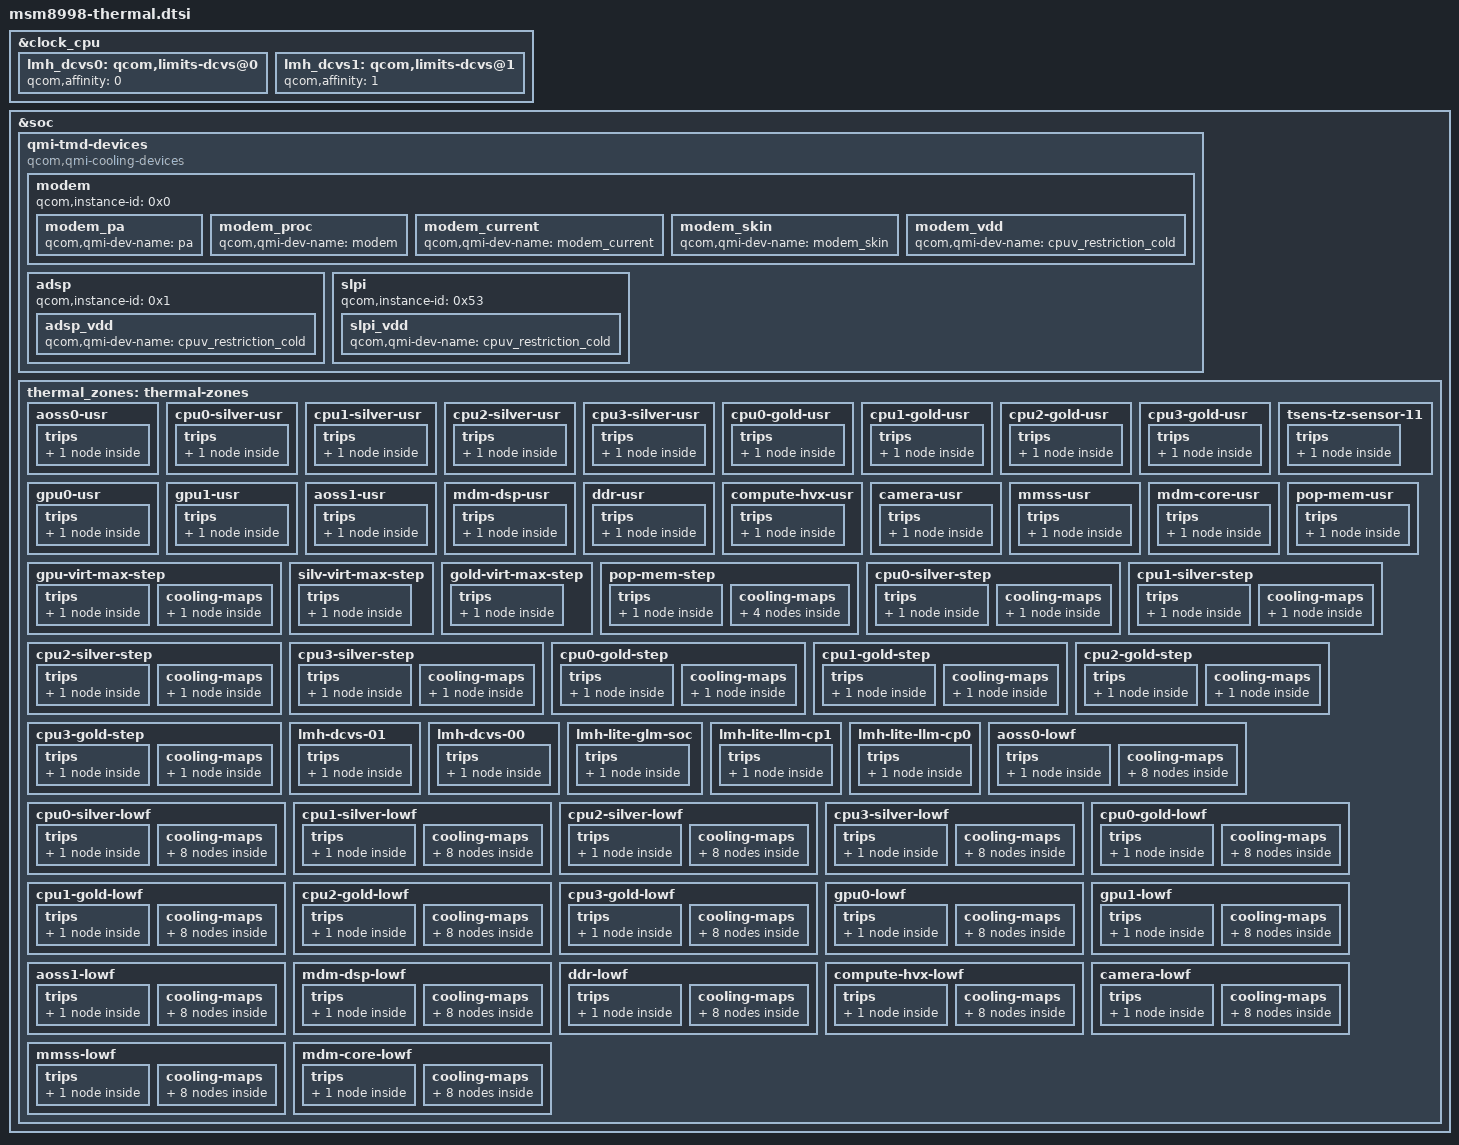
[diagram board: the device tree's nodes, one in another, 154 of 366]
/* Copyright (c) 2017-2018, The Linux Foundation. All rights reserved.
 * Copyright (C) 2018, AngeloGioacchino Del Regno <kholk11@gmail.com>
 *
 * This program is free software; you can redistribute it and/or modify
 * it under the terms of the GNU General Public License version 2 and
 * only version 2 as published by the Free Software Foundation.
 *
 * This program is distributed in the hope that it will be useful,
 * but WITHOUT ANY WARRANTY; without even the implied warranty of
 * MERCHANTABILITY or FITNESS FOR A PARTICULAR PURPOSE.  See the
 * GNU General Public License for more details.
 */

#include <dt-bindings/thermal/thermal.h>

&clock_cpu {
	lmh_dcvs0: qcom,limits-dcvs@0 {
		qcom,affinity = <0>;
		#thermal-sensor-cells = <0>;
	};

	lmh_dcvs1: qcom,limits-dcvs@1 {
		qcom,affinity = <1>;
		#thermal-sensor-cells = <0>;
	};
};

&soc {
	qmi-tmd-devices {
		compatible = "qcom,qmi-cooling-devices";

		modem {
			qcom,instance-id = <0x0>;

			modem_pa: modem_pa {
				qcom,qmi-dev-name = "pa";
				#cooling-cells = <2>;
			};

			modem_proc: modem_proc {
				qcom,qmi-dev-name = "modem";
				#cooling-cells = <2>;
			};

			modem_current: modem_current {
				qcom,qmi-dev-name = "modem_current";
				#cooling-cells = <2>;
			};

			modem_skin: modem_skin {
				qcom,qmi-dev-name = "modem_skin";
				#cooling-cells = <2>;
			};

			modem_vdd: modem_vdd {
				qcom,qmi-dev-name = "cpuv_restriction_cold";
				#cooling-cells = <2>;
			};
		};

		adsp {
			qcom,instance-id = <0x1>;

			adsp_vdd: adsp_vdd {
				qcom,qmi-dev-name = "cpuv_restriction_cold";
				#cooling-cells = <2>;
			};
		};

		slpi {
			qcom,instance-id = <0x53>;

			slpi_vdd: slpi_vdd {
				qcom,qmi-dev-name = "cpuv_restriction_cold";
				#cooling-cells = <2>;
			};
		};
	};

	thermal_zones: thermal-zones {
		aoss0-usr {
			polling-delay-passive = <0>;
			polling-delay = <0>;
			thermal-governor = "user_space";
			thermal-sensors = <&tsens0 0>;
			trips {
				active-config0 {
					temperature = <125000>;
					hysteresis = <1000>;
					type = "passive";
				};
			};
		};

		cpu0-silver-usr {
			polling-delay-passive = <0>;
			polling-delay = <0>;
			thermal-governor = "user_space";
			thermal-sensors = <&tsens0 1>;
			trips {
				active-config0 {
					temperature = <125000>;
					hysteresis = <1000>;
					type = "passive";
				};
			};
		};

		cpu1-silver-usr {
			polling-delay-passive = <0>;
			polling-delay = <0>;
			thermal-governor = "user_space";
			thermal-sensors = <&tsens0 2>;
			trips {
				active-config0 {
					temperature = <125000>;
					hysteresis = <1000>;
					type = "passive";
				};
			};
		};

		cpu2-silver-usr {
			polling-delay-passive = <0>;
			polling-delay = <0>;
			thermal-governor = "user_space";
			thermal-sensors = <&tsens0 3>;
			trips {
				active-config0 {
					temperature = <125000>;
					hysteresis = <1000>;
					type = "passive";
				};
			};
		};

		cpu3-silver-usr {
			polling-delay-passive = <0>;
			polling-delay = <0>;
			thermal-sensors = <&tsens0 4>;
			thermal-governor = "user_space";
			trips {
				active-config0 {
					temperature = <125000>;
					hysteresis = <1000>;
					type = "passive";
				};
			};
		};

		cpu0-gold-usr {
			polling-delay-passive = <0>;
			polling-delay = <0>;
			thermal-sensors = <&tsens0 7>;
			thermal-governor = "user_space";
			trips {
				active-config0 {
					temperature = <125000>;
					hysteresis = <1000>;
					type = "passive";
				};
			};
		};

		cpu1-gold-usr {
			polling-delay-passive = <0>;
			polling-delay = <0>;
			thermal-sensors = <&tsens0 8>;
			thermal-governor = "user_space";
			trips {
				active-config0 {
					temperature = <125000>;
					hysteresis = <1000>;
					type = "passive";
				};
			};
		};

		cpu2-gold-usr {
			polling-delay-passive = <0>;
			polling-delay = <0>;
			thermal-sensors = <&tsens0 9>;
			thermal-governor = "user_space";
			trips {
				active-config0 {
					temperature = <125000>;
					hysteresis = <1000>;
					type = "passive";
				};
			};
		};

		cpu3-gold-usr {
			polling-delay-passive = <0>;
			polling-delay = <0>;
			thermal-sensors = <&tsens0 10>;
			thermal-governor = "user_space";
			trips {
				active-config0 {
					temperature = <125000>;
					hysteresis = <1000>;
					type = "passive";
				};
			};
		};

		tsens-tz-sensor-11 {
			polling-delay-passive = <0>;
			polling-delay = <0>;
			thermal-sensors = <&tsens0 11>;
			thermal-governor = "user_space";
			trips {
				active-config0 {
					temperature = <125000>;
					hysteresis = <1000>;
					type = "passive";
				};
			};
		};

		gpu0-usr {
			polling-delay-passive = <0>;
			polling-delay = <0>;
			thermal-sensors = <&tsens0 12>;
			thermal-governor = "user_space";
			trips {
				active-config0 {
					temperature = <125000>;
					hysteresis = <1000>;
					type = "passive";
				};
			};
		};

		gpu1-usr {
			polling-delay-passive = <0>;
			polling-delay = <0>;
			thermal-governor = "user_space";
			thermal-sensors = <&tsens0 13>;
			trips {
				active-config0 {
					temperature = <125000>;
					hysteresis = <1000>;
					type = "passive";
				};
			};
		};

		aoss1-usr {
			polling-delay-passive = <0>;
			polling-delay = <0>;
			thermal-sensors = <&tsens1 0>;
			thermal-governor = "user_space";
			trips {
				active-config0 {
					temperature = <125000>;
					hysteresis = <1000>;
					type = "passive";
				};
			};
		};

		mdm-dsp-usr {
			polling-delay-passive = <0>;
			polling-delay = <0>;
			thermal-sensors = <&tsens1 1>;
			thermal-governor = "user_space";
			trips {
				active-config0 {
					temperature = <125000>;
					hysteresis = <1000>;
					type = "passive";
				};
			};
		};

		ddr-usr {
			polling-delay-passive = <0>;
			polling-delay = <0>;
			thermal-sensors = <&tsens1 2>;
			thermal-governor = "user_space";
			trips {
				active-config0 {
					temperature = <125000>;
					hysteresis = <1000>;
					type = "passive";
				};
			};
		};

		compute-hvx-usr {
			polling-delay-passive = <0>;
			polling-delay = <0>;
			thermal-sensors = <&tsens1 3>;
			thermal-governor = "user_space";
			trips {
				active-config0 {
					temperature = <125000>;
					hysteresis = <1000>;
					type = "passive";
				};
			};
		};

		camera-usr {
			polling-delay-passive = <0>;
			polling-delay = <0>;
			thermal-sensors = <&tsens1 4>;
			thermal-governor = "user_space";
			trips {
				active-config0 {
					temperature = <125000>;
					hysteresis = <1000>;
					type = "passive";
				};
			};
		};

		mmss-usr {
			polling-delay-passive = <0>;
			polling-delay = <0>;
			thermal-sensors = <&tsens1 5>;
			thermal-governor = "user_space";
			trips {
				active-config0 {
					temperature = <125000>;
					hysteresis = <1000>;
					type = "passive";
				};
			};
		};

		mdm-core-usr {
			polling-delay-passive = <0>;
			polling-delay = <0>;
			thermal-sensors = <&tsens1 6>;
			thermal-governor = "user_space";
			trips {
				active-config0 {
					temperature = <125000>;
					hysteresis = <1000>;
					type = "passive";
				};
			};
		};

		pop-mem-usr {
			polling-delay-passive = <0>;
			polling-delay = <0>;
			thermal-sensors = <&tsens1 7>;
			thermal-governor = "user_space";
			trips {
				active-config0 {
					temperature = <125000>;
					hysteresis = <1000>;
					type = "passive";
				};
			};
		};

		gpu-virt-max-step {
			polling-delay-passive = <10>;
			polling-delay = <100>;
			thermal-governor = "step_wise";
			trips {
				gpu_trip0: gpu-trip0 {
					temperature = <95000>;
					hysteresis = <0>;
					type = "passive";
				};
			};
			cooling-maps {
				gpu_cdev0 {
					trip = <&gpu_trip0>;
					cooling-device =
						<&msm_gpu 0 THERMAL_NO_LIMIT>;
				};
			};
		};

		silv-virt-max-step {
			polling-delay-passive = <0>;
			polling-delay = <0>;
			thermal-governor = "step_wise";
			trips {
				silver-trip {
					temperature = <120000>;
					hysteresis = <0>;
					type = "passive";
				};
			};
		};

		gold-virt-max-step {
			polling-delay-passive = <0>;
			polling-delay = <0>;
			thermal-governor = "step_wise";
			trips {
				gold-trip {
					temperature = <120000>;
					hysteresis = <0>;
					type = "passive";
				};
			};
		};

		pop-mem-step {
			polling-delay-passive = <10>;
			polling-delay = <0>;
			thermal-sensors = <&tsens1 7>;
			thermal-governor = "step_wise";
			trips {
				pop_trip: pop-trip {
					temperature = <95000>;
					hysteresis = <0>;
					type = "passive";
				};
			};
			cooling-maps {
				pop_cdev4 {
					trip = <&pop_trip>;
					cooling-device =
						<&CPU4 THERMAL_NO_LIMIT
							(THERMAL_MAX_LIMIT-1)>;
				};
				pop_cdev5 {
					trip = <&pop_trip>;
					cooling-device =
						<&CPU5 THERMAL_NO_LIMIT
							(THERMAL_MAX_LIMIT-1)>;
				};
				pop_cdev6 {
					trip = <&pop_trip>;
					cooling-device =
						<&CPU6 THERMAL_NO_LIMIT
							(THERMAL_MAX_LIMIT-1)>;
				};
				pop_cdev7 {
					trip = <&pop_trip>;
					cooling-device =
						<&CPU7 THERMAL_NO_LIMIT
							(THERMAL_MAX_LIMIT-1)>;
				};
			};
		};

		cpu0-silver-step {
			polling-delay-passive = <100>;
			polling-delay = <0>;
			thermal-sensors = <&tsens0 1>;
			thermal-governor = "step_wise";
			trips {
				emerg_config0: emerg-config0 {
					temperature = <110000>;
					hysteresis = <10000>;
					type = "passive";
				};
			};
			cooling-maps {
				emerg_cdev0 {
					trip = <&emerg_config0>;
					cooling-device =
						<&CPU0 THERMAL_MAX_LIMIT
							THERMAL_MAX_LIMIT>;
				};
			};
		};

		cpu1-silver-step {
			polling-delay-passive = <100>;
			polling-delay = <0>;
			thermal-sensors = <&tsens0 2>;
			thermal-governor = "step_wise";
			trips {
				emerg_config1: emerg-config1 {
					temperature = <110000>;
					hysteresis = <10000>;
					type = "passive";
				};
			};
			cooling-maps {
				emerg_cdev1 {
					trip = <&emerg_config1>;
					cooling-device =
						<&CPU1 THERMAL_MAX_LIMIT
							THERMAL_MAX_LIMIT>;
				};
			};
		};

		cpu2-silver-step {
			polling-delay-passive = <100>;
			polling-delay = <0>;
			thermal-sensors = <&tsens0 3>;
			thermal-governor = "step_wise";
			trips {
				emerg_config2: emerg-config2 {
					temperature = <110000>;
					hysteresis = <10000>;
					type = "passive";
				};
			};
			cooling-maps {
				emerg_cdev2 {
					trip = <&emerg_config2>;
					cooling-device =
						<&CPU2 THERMAL_MAX_LIMIT
							THERMAL_MAX_LIMIT>;
				};
			};
		};

		cpu3-silver-step {
			polling-delay-passive = <100>;
			polling-delay = <0>;
			thermal-sensors = <&tsens0 4>;
			thermal-governor = "step_wise";
			trips {
				emerg_config3: emerg-config3 {
					temperature = <110000>;
					hysteresis = <10000>;
					type = "passive";
				};
			};
			cooling-maps {
				emerg_cdev3 {
					trip = <&emerg_config3>;
					cooling-device =
						<&CPU3 THERMAL_MAX_LIMIT
							THERMAL_MAX_LIMIT>;
				};
			};
		};

		cpu0-gold-step {
			polling-delay-passive = <100>;
			polling-delay = <0>;
			thermal-sensors = <&tsens0 7>;
			thermal-governor = "step_wise";
			trips {
				emerg_config4: emerg-config4 {
					temperature = <110000>;
					hysteresis = <10000>;
					type = "passive";
				};
			};
			cooling-maps {
				emerg_cdev4 {
					trip = <&emerg_config4>;
					cooling-device =
						<&CPU4 THERMAL_MAX_LIMIT
							THERMAL_MAX_LIMIT>;
				};
			};
		};

		cpu1-gold-step {
			polling-delay-passive = <100>;
			polling-delay = <0>;
			thermal-sensors = <&tsens0 8>;
			thermal-governor = "step_wise";
			trips {
				emerg_config5: emerg-config5 {
					temperature = <110000>;
					hysteresis = <10000>;
					type = "passive";
				};
			};
			cooling-maps {
				emerg_cdev5 {
					trip = <&emerg_config5>;
					cooling-device =
						<&CPU5 THERMAL_MAX_LIMIT
							THERMAL_MAX_LIMIT>;
				};
			};
		};

		cpu2-gold-step {
			polling-delay-passive = <100>;
			polling-delay = <0>;
			thermal-sensors = <&tsens0 9>;
			thermal-governor = "step_wise";
			trips {
				emerg_config6: emerg-config6 {
					temperature = <110000>;
					hysteresis = <10000>;
					type = "passive";
				};
			};
			cooling-maps {
				emerg_cdev6 {
					trip = <&emerg_config6>;
					cooling-device =
						<&CPU6 THERMAL_MAX_LIMIT
							THERMAL_MAX_LIMIT>;
				};
			};
		};

		cpu3-gold-step {
			polling-delay-passive = <100>;
			polling-delay = <0>;
			thermal-sensors = <&tsens0 10>;
			thermal-governor = "step_wise";
			trips {
				emerg_config7: emerg-config7 {
					temperature = <110000>;
					hysteresis = <10000>;
					type = "passive";
				};
			};
			cooling-maps {
				emerg_cdev7 {
					trip = <&emerg_config7>;
					cooling-device =
						<&CPU7 THERMAL_MAX_LIMIT
							THERMAL_MAX_LIMIT>;
				};
			};
		};

		lmh-dcvs-01 {
			polling-delay-passive = <0>;
			polling-delay = <0>;
			thermal-governor = "user_space";
			thermal-sensors = <&lmh_dcvs1>;

			trips {
				active-config {
					temperature = <95000>;
					hysteresis = <30000>;
					type = "passive";
				};
			};
		};

		lmh-dcvs-00 {
			polling-delay-passive = <0>;
			polling-delay = <0>;
			thermal-governor = "user_space";
			thermal-sensors = <&lmh_dcvs0>;

			trips {
				active-config {
					temperature = <95000>;
					hysteresis = <30000>;
					type = "passive";
				};
			};
		};

		lmh-lite-glm-soc {
			polling-delay-passive = <0>;
			polling-delay = <0>;
			thermal-governor = "user_space";
			thermal-sensors = <&lmh_lite 0>;

			trips {
				active-config {
					temperature = <125000>;
					hysteresis = <30000>;
					type = "passive";
				};
			};
		};

		lmh-lite-llm-cp1 {
			polling-delay-passive = <0>;
			polling-delay = <0>;
			thermal-governor = "user_space";
			thermal-sensors = <&lmh_lite 1>;

			trips {
				active-config {
					temperature = <125000>;
					hysteresis = <30000>;
					type = "passive";
				};
			};
		};

		lmh-lite-llm-cp0 {
			polling-delay-passive = <0>;
			polling-delay = <0>;
			thermal-governor = "user_space";
			thermal-sensors = <&lmh_lite 2>;

			trips {
				active-config {
					temperature = <125000>;
					hysteresis = <30000>;
					type = "passive";
				};
			};
		};

		aoss0-lowf {
			polling-delay-passive = <0>;
			polling-delay = <0>;
			thermal-governor = "low_limits_floor";
			thermal-sensors = <&tsens0 0>;
			wake-capable-sensor;
			tracks-low;
			trips {
				aoss0_trip: aoss0-trip {
					temperature = <5000>;
					hysteresis = <5000>;
					type = "passive";
				};
			};
			cooling-maps {
				cpu0_vdd_cdev {
					trip = <&aoss0_trip>;
					cooling-device = <&CPU0 4 4>;
				};
				cpu4_vdd_cdev {
					trip = <&aoss0_trip>;
					cooling-device = <&CPU4 9 9>;
				};
				gpu_vdd_cdev {
					trip = <&aoss0_trip>;
					cooling-device = <&msm_gpu 1 1>;
				};
				cx_vdd_cdev {
					trip = <&aoss0_trip>;
					cooling-device = <&cx_cdev 0 0>;
				};
				mx_vdd_cdev {
					trip = <&aoss0_trip>;
					cooling-device = <&mx_cdev 0 0>;
				};
				modem_vdd_cdev {
					trip = <&aoss0_trip>;
					cooling-device = <&modem_vdd 0 0>;
				};
				adsp_vdd_cdev {
					trip = <&aoss0_trip>;
					cooling-device = <&adsp_vdd 0 0>;
				};
				slpi_vdd_cdev {
					trip = <&aoss0_trip>;
					cooling-device = <&slpi_vdd 0 0>;
				};
			};
		};

		cpu0-silver-lowf {
			polling-delay-passive = <0>;
			polling-delay = <0>;
			thermal-governor = "low_limits_floor";
			thermal-sensors = <&tsens0 1>;
			wake-capable-sensor;
			tracks-low;
			trips {
				cpu0_trip: cpu0-trip {
					temperature = <5000>;
					hysteresis = <5000>;
					type = "passive";
				};
			};
			cooling-maps {
				cpu0_vdd_cdev {
					trip = <&cpu0_trip>;
					cooling-device = <&CPU0 4 4>;
				};
				cpu4_vdd_cdev {
					trip = <&cpu0_trip>;
					cooling-device = <&CPU4 9 9>;
				};
				gpu_vdd_cdev {
					trip = <&cpu0_trip>;
					cooling-device = <&msm_gpu 1 1>;
				};
				cx_vdd_cdev {
					trip = <&cpu0_trip>;
					cooling-device = <&cx_cdev 0 0>;
				};
				mx_vdd_cdev {
					trip = <&cpu0_trip>;
					cooling-device = <&mx_cdev 0 0>;
				};
				modem_vdd_cdev {
					trip = <&cpu0_trip>;
					cooling-device = <&modem_vdd 0 0>;
				};
				adsp_vdd_cdev {
					trip = <&cpu0_trip>;
					cooling-device = <&adsp_vdd 0 0>;
				};
				slpi_vdd_cdev {
					trip = <&cpu0_trip>;
					cooling-device = <&slpi_vdd 0 0>;
				};
			};
		};

		cpu1-silver-lowf {
			polling-delay-passive = <0>;
			polling-delay = <0>;
			thermal-governor = "low_limits_floor";
			thermal-sensors = <&tsens0 2>;
			wake-capable-sensor;
			tracks-low;
			trips {
				cpu1_trip: cpu1-trip {
					temperature = <5000>;
					hysteresis = <5000>;
					type = "passive";
				};
			};
			cooling-maps {
				cpu0_vdd_cdev {
					trip = <&cpu1_trip>;
					cooling-device = <&CPU0 4 4>;
				};
				cpu4_vdd_cdev {
					trip = <&cpu1_trip>;
					cooling-device = <&CPU4 9 9>;
				};
				gpu_vdd_cdev {
					trip = <&cpu1_trip>;
					cooling-device = <&msm_gpu 1 1>;
				};
				cx_vdd_cdev {
					trip = <&cpu1_trip>;
					cooling-device = <&cx_cdev 0 0>;
				};
				mx_vdd_cdev {
					trip = <&cpu1_trip>;
					cooling-device = <&mx_cdev 0 0>;
				};
				modem_vdd_cdev {
					trip = <&cpu1_trip>;
					cooling-device = <&modem_vdd 0 0>;
				};
				adsp_vdd_cdev {
					trip = <&cpu1_trip>;
					cooling-device = <&adsp_vdd 0 0>;
				};
				slpi_vdd_cdev {
					trip = <&cpu1_trip>;
					cooling-device = <&slpi_vdd 0 0>;
				};
			};
		};

		cpu2-silver-lowf {
			polling-delay-passive = <0>;
			polling-delay = <0>;
			thermal-governor = "low_limits_floor";
			thermal-sensors = <&tsens0 3>;
			wake-capable-sensor;
			tracks-low;
			trips {
				cpu2_trip: cpu2-trip {
					temperature = <5000>;
					hysteresis = <5000>;
					type = "passive";
				};
			};
			cooling-maps {
				cpu0_vdd_cdev {
					trip = <&cpu2_trip>;
					cooling-device = <&CPU0 4 4>;
				};
				cpu4_vdd_cdev {
					trip = <&cpu2_trip>;
					cooling-device = <&CPU4 9 9>;
				};
				gpu_vdd_cdev {
					trip = <&cpu2_trip>;
					cooling-device = <&msm_gpu 1 1>;
				};
				cx_vdd_cdev {
					trip = <&cpu2_trip>;
					cooling-device = <&cx_cdev 0 0>;
				};
				mx_vdd_cdev {
					trip = <&cpu2_trip>;
					cooling-device = <&mx_cdev 0 0>;
				};
				modem_vdd_cdev {
					trip = <&cpu2_trip>;
					cooling-device = <&modem_vdd 0 0>;
				};
				adsp_vdd_cdev {
					trip = <&cpu2_trip>;
					cooling-device = <&adsp_vdd 0 0>;
				};
				slpi_vdd_cdev {
					trip = <&cpu2_trip>;
					cooling-device = <&slpi_vdd 0 0>;
				};
			};
		};

		cpu3-silver-lowf {
			polling-delay-passive = <0>;
			polling-delay = <0>;
			thermal-governor = "low_limits_floor";
			thermal-sensors = <&tsens0 4>;
			wake-capable-sensor;
			tracks-low;
			trips {
				cpu3_trip: cpu3-trip {
					temperature = <5000>;
					hysteresis = <5000>;
					type = "passive";
				};
			};
			cooling-maps {
				cpu0_vdd_cdev {
					trip = <&cpu3_trip>;
					cooling-device = <&CPU0 4 4>;
				};
				cpu4_vdd_cdev {
					trip = <&cpu3_trip>;
					cooling-device = <&CPU4 9 9>;
				};
				gpu_vdd_cdev {
					trip = <&cpu3_trip>;
					cooling-device = <&msm_gpu 1 1>;
				};
				cx_vdd_cdev {
					trip = <&cpu3_trip>;
					cooling-device = <&cx_cdev 0 0>;
				};
				mx_vdd_cdev {
					trip = <&cpu3_trip>;
					cooling-device = <&mx_cdev 0 0>;
				};
				modem_vdd_cdev {
					trip = <&cpu3_trip>;
					cooling-device = <&modem_vdd 0 0>;
				};
				adsp_vdd_cdev {
					trip = <&cpu3_trip>;
					cooling-device = <&adsp_vdd 0 0>;
				};
				slpi_vdd_cdev {
					trip = <&cpu3_trip>;
					cooling-device = <&slpi_vdd 0 0>;
				};
			};
		};

		cpu0-gold-lowf {
			polling-delay-passive = <0>;
			polling-delay = <0>;
			thermal-governor = "low_limits_floor";
			thermal-sensors = <&tsens0 7>;
			wake-capable-sensor;
			tracks-low;
			trips {
				cpug0_trip: cpug0-trip {
					temperature = <5000>;
					hysteresis = <5000>;
					type = "passive";
				};
			};
			cooling-maps {
				cpu0_vdd_cdev {
					trip = <&cpug0_trip>;
					cooling-device = <&CPU0 4 4>;
				};
				cpu4_vdd_cdev {
					trip = <&cpug0_trip>;
					cooling-device = <&CPU4 9 9>;
				};
				gpu_vdd_cdev {
					trip = <&cpug0_trip>;
					cooling-device = <&msm_gpu 1 1>;
				};
				cx_vdd_cdev {
					trip = <&cpug0_trip>;
					cooling-device = <&cx_cdev 0 0>;
				};
				mx_vdd_cdev {
					trip = <&cpug0_trip>;
					cooling-device = <&mx_cdev 0 0>;
				};
				modem_vdd_cdev {
					trip = <&cpug0_trip>;
					cooling-device = <&modem_vdd 0 0>;
				};
				adsp_vdd_cdev {
					trip = <&cpug0_trip>;
					cooling-device = <&adsp_vdd 0 0>;
				};
				slpi_vdd_cdev {
					trip = <&cpug0_trip>;
					cooling-device = <&slpi_vdd 0 0>;
				};
			};
		};

		cpu1-gold-lowf {
			polling-delay-passive = <0>;
			polling-delay = <0>;
			thermal-governor = "low_limits_floor";
			thermal-sensors = <&tsens0 8>;
			wake-capable-sensor;
			tracks-low;
			trips {
				cpug1_trip: cpug1-trip {
					temperature = <5000>;
					hysteresis = <5000>;
					type = "passive";
				};
			};
			cooling-maps {
				cpu0_vdd_cdev {
					trip = <&cpug1_trip>;
					cooling-device = <&CPU0 4 4>;
				};
				cpu4_vdd_cdev {
					trip = <&cpug1_trip>;
					cooling-device = <&CPU4 9 9>;
				};
				gpu_vdd_cdev {
					trip = <&cpug1_trip>;
					cooling-device = <&msm_gpu 1 1>;
				};
				cx_vdd_cdev {
					trip = <&cpug1_trip>;
					cooling-device = <&cx_cdev 0 0>;
				};
				mx_vdd_cdev {
					trip = <&cpug1_trip>;
					cooling-device = <&mx_cdev 0 0>;
				};
				modem_vdd_cdev {
					trip = <&cpug1_trip>;
					cooling-device = <&modem_vdd 0 0>;
				};
				adsp_vdd_cdev {
					trip = <&cpug1_trip>;
					cooling-device = <&adsp_vdd 0 0>;
				};
				slpi_vdd_cdev {
					trip = <&cpug1_trip>;
					cooling-device = <&slpi_vdd 0 0>;
				};
			};
		};

		cpu2-gold-lowf {
			polling-delay-passive = <0>;
			polling-delay = <0>;
			thermal-governor = "low_limits_floor";
			thermal-sensors = <&tsens0 9>;
			wake-capable-sensor;
			tracks-low;
			trips {
				cpug2_trip: cpug2-trip {
					temperature = <5000>;
					hysteresis = <5000>;
					type = "passive";
				};
			};
			cooling-maps {
				cpu0_vdd_cdev {
					trip = <&cpug2_trip>;
					cooling-device = <&CPU0 4 4>;
				};
				cpu4_vdd_cdev {
					trip = <&cpug2_trip>;
					cooling-device = <&CPU4 9 9>;
				};
				gpu_vdd_cdev {
					trip = <&cpug2_trip>;
					cooling-device = <&msm_gpu 1 1>;
				};
				cx_vdd_cdev {
					trip = <&cpug2_trip>;
					cooling-device = <&cx_cdev 0 0>;
				};
				mx_vdd_cdev {
					trip = <&cpug2_trip>;
					cooling-device = <&mx_cdev 0 0>;
				};
				modem_vdd_cdev {
					trip = <&cpug2_trip>;
					cooling-device = <&modem_vdd 0 0>;
				};
				adsp_vdd_cdev {
					trip = <&cpug2_trip>;
					cooling-device = <&adsp_vdd 0 0>;
				};
				slpi_vdd_cdev {
					trip = <&cpug2_trip>;
					cooling-device = <&slpi_vdd 0 0>;
				};
			};
		};

		cpu3-gold-lowf {
			polling-delay-passive = <0>;
			polling-delay = <0>;
			thermal-governor = "low_limits_floor";
			thermal-sensors = <&tsens0 10>;
			wake-capable-sensor;
			tracks-low;
			trips {
				cpug3_trip: cpug3-trip {
					temperature = <5000>;
					hysteresis = <5000>;
					type = "passive";
				};
			};
			cooling-maps {
				cpu0_vdd_cdev {
					trip = <&cpug3_trip>;
					cooling-device = <&CPU0 4 4>;
				};
				cpu4_vdd_cdev {
					trip = <&cpug3_trip>;
					cooling-device = <&CPU4 9 9>;
				};
				gpu_vdd_cdev {
					trip = <&cpug3_trip>;
					cooling-device = <&msm_gpu 1 1>;
				};
				cx_vdd_cdev {
					trip = <&cpug3_trip>;
					cooling-device = <&cx_cdev 0 0>;
				};
				mx_vdd_cdev {
					trip = <&cpug3_trip>;
					cooling-device = <&mx_cdev 0 0>;
				};
				modem_vdd_cdev {
					trip = <&cpug3_trip>;
					cooling-device = <&modem_vdd 0 0>;
				};
				adsp_vdd_cdev {
					trip = <&cpug3_trip>;
					cooling-device = <&adsp_vdd 0 0>;
				};
				slpi_vdd_cdev {
					trip = <&cpug3_trip>;
					cooling-device = <&slpi_vdd 0 0>;
				};
			};
		};

		gpu0-lowf {
			polling-delay-passive = <0>;
			polling-delay = <0>;
			thermal-governor = "low_limits_floor";
			thermal-sensors = <&tsens0 12>;
			wake-capable-sensor;
			tracks-low;
			trips {
				gpu0_trip_l: gpu0-trip {
					temperature = <5000>;
					hysteresis = <5000>;
					type = "passive";
				};
			};
			cooling-maps {
				cpu0_vdd_cdev {
					trip = <&gpu0_trip_l>;
					cooling-device = <&CPU0 4 4>;
				};
				cpu4_vdd_cdev {
					trip = <&gpu0_trip_l>;
					cooling-device = <&CPU4 9 9>;
				};
				gpu_vdd_cdev {
					trip = <&gpu0_trip_l>;
					cooling-device = <&msm_gpu 1 1>;
				};
				cx_vdd_cdev {
					trip = <&gpu0_trip_l>;
					cooling-device = <&cx_cdev 0 0>;
				};
				mx_vdd_cdev {
					trip = <&gpu0_trip_l>;
					cooling-device = <&mx_cdev 0 0>;
				};
				modem_vdd_cdev {
					trip = <&gpu0_trip_l>;
					cooling-device = <&modem_vdd 0 0>;
				};
				adsp_vdd_cdev {
					trip = <&gpu0_trip_l>;
					cooling-device = <&adsp_vdd 0 0>;
				};
				slpi_vdd_cdev {
					trip = <&gpu0_trip_l>;
					cooling-device = <&slpi_vdd 0 0>;
				};
			};
		};

		gpu1-lowf {
			polling-delay-passive = <0>;
			polling-delay = <0>;
			thermal-governor = "low_limits_floor";
			thermal-sensors = <&tsens0 13>;
			wake-capable-sensor;
			tracks-low;
			trips {
				gpu1_trip_l: gpu1-trip_l {
					temperature = <5000>;
					hysteresis = <5000>;
					type = "passive";
				};
			};
			cooling-maps {
				cpu0_vdd_cdev {
					trip = <&gpu1_trip_l>;
					cooling-device = <&CPU0 4 4>;
				};
				cpu4_vdd_cdev {
					trip = <&gpu1_trip_l>;
					cooling-device = <&CPU4 9 9>;
				};
				gpu_vdd_cdev {
					trip = <&gpu1_trip_l>;
					cooling-device = <&msm_gpu 1 1>;
				};
				cx_vdd_cdev {
					trip = <&gpu1_trip_l>;
					cooling-device = <&cx_cdev 0 0>;
				};
				mx_vdd_cdev {
					trip = <&gpu1_trip_l>;
					cooling-device = <&mx_cdev 0 0>;
				};
				modem_vdd_cdev {
					trip = <&gpu1_trip_l>;
					cooling-device = <&modem_vdd 0 0>;
				};
				adsp_vdd_cdev {
					trip = <&gpu1_trip_l>;
					cooling-device = <&adsp_vdd 0 0>;
				};
				slpi_vdd_cdev {
					trip = <&gpu1_trip_l>;
					cooling-device = <&slpi_vdd 0 0>;
				};
			};
		};

		aoss1-lowf {
			polling-delay-passive = <0>;
			polling-delay = <0>;
			thermal-governor = "low_limits_floor";
			thermal-sensors = <&tsens1 0>;
			wake-capable-sensor;
			tracks-low;
			trips {
				aoss1_trip: aoss1-trip {
					temperature = <5000>;
					hysteresis = <5000>;
					type = "passive";
				};
			};
			cooling-maps {
				cpu0_vdd_cdev {
					trip = <&aoss1_trip>;
					cooling-device = <&CPU0 4 4>;
				};
				cpu4_vdd_cdev {
					trip = <&aoss1_trip>;
					cooling-device = <&CPU4 9 9>;
				};
				gpu_vdd_cdev {
					trip = <&aoss1_trip>;
					cooling-device = <&msm_gpu 1 1>;
				};
				cx_vdd_cdev {
					trip = <&aoss1_trip>;
					cooling-device = <&cx_cdev 0 0>;
				};
				mx_vdd_cdev {
					trip = <&aoss1_trip>;
					cooling-device = <&mx_cdev 0 0>;
				};
				modem_vdd_cdev {
					trip = <&aoss1_trip>;
					cooling-device = <&modem_vdd 0 0>;
				};
				adsp_vdd_cdev {
					trip = <&aoss1_trip>;
					cooling-device = <&adsp_vdd 0 0>;
				};
				slpi_vdd_cdev {
					trip = <&aoss1_trip>;
					cooling-device = <&slpi_vdd 0 0>;
				};
			};
		};

		mdm-dsp-lowf {
			polling-delay-passive = <0>;
			polling-delay = <0>;
			thermal-governor = "low_limits_floor";
			thermal-sensors = <&tsens1 1>;
			wake-capable-sensor;
			tracks-low;
			trips {
				dsp_trip: dsp-trip {
					temperature = <5000>;
					hysteresis = <5000>;
					type = "passive";
				};
			};
			cooling-maps {
				cpu0_vdd_cdev {
					trip = <&dsp_trip>;
					cooling-device = <&CPU0 4 4>;
				};
				cpu4_vdd_cdev {
					trip = <&dsp_trip>;
					cooling-device = <&CPU4 9 9>;
				};
				gpu_vdd_cdev {
					trip = <&dsp_trip>;
					cooling-device = <&msm_gpu 1 1>;
				};
				cx_vdd_cdev {
					trip = <&dsp_trip>;
					cooling-device = <&cx_cdev 0 0>;
				};
				mx_vdd_cdev {
					trip = <&dsp_trip>;
					cooling-device = <&mx_cdev 0 0>;
				};
				modem_vdd_cdev {
					trip = <&dsp_trip>;
					cooling-device = <&modem_vdd 0 0>;
				};
				adsp_vdd_cdev {
					trip = <&dsp_trip>;
					cooling-device = <&adsp_vdd 0 0>;
				};
				slpi_vdd_cdev {
					trip = <&dsp_trip>;
					cooling-device = <&slpi_vdd 0 0>;
				};
			};
		};

		ddr-lowf {
			polling-delay-passive = <0>;
			polling-delay = <0>;
			thermal-governor = "low_limits_floor";
			thermal-sensors = <&tsens1 2>;
			wake-capable-sensor;
			tracks-low;
			trips {
				ddr_trip: ddr-trip {
					temperature = <5000>;
					hysteresis = <5000>;
					type = "passive";
				};
			};
			cooling-maps {
				cpu0_vdd_cdev {
					trip = <&ddr_trip>;
					cooling-device = <&CPU0 4 4>;
				};
				cpu4_vdd_cdev {
					trip = <&ddr_trip>;
					cooling-device = <&CPU4 9 9>;
				};
				gpu_vdd_cdev {
					trip = <&ddr_trip>;
					cooling-device = <&msm_gpu 1 1>;
				};
				cx_vdd_cdev {
					trip = <&ddr_trip>;
					cooling-device = <&cx_cdev 0 0>;
				};
				mx_vdd_cdev {
					trip = <&ddr_trip>;
					cooling-device = <&mx_cdev 0 0>;
				};
				modem_vdd_cdev {
					trip = <&ddr_trip>;
					cooling-device = <&modem_vdd 0 0>;
				};
				adsp_vdd_cdev {
					trip = <&ddr_trip>;
					cooling-device = <&adsp_vdd 0 0>;
				};
				slpi_vdd_cdev {
					trip = <&ddr_trip>;
					cooling-device = <&slpi_vdd 0 0>;
				};
			};
		};

		compute-hvx-lowf {
			polling-delay-passive = <0>;
			polling-delay = <0>;
			thermal-governor = "low_limits_floor";
			thermal-sensors = <&tsens1 3>;
			wake-capable-sensor;
			tracks-low;
			trips {
				hvx_trip: hvx-trip {
					temperature = <5000>;
					hysteresis = <5000>;
					type = "passive";
				};
			};
			cooling-maps {
				cpu0_vdd_cdev {
					trip = <&hvx_trip>;
					cooling-device = <&CPU0 4 4>;
				};
				cpu4_vdd_cdev {
					trip = <&hvx_trip>;
					cooling-device = <&CPU4 9 9>;
				};
				gpu_vdd_cdev {
					trip = <&hvx_trip>;
					cooling-device = <&msm_gpu 1 1>;
				};
				cx_vdd_cdev {
					trip = <&hvx_trip>;
					cooling-device = <&cx_cdev 0 0>;
				};
				mx_vdd_cdev {
					trip = <&hvx_trip>;
					cooling-device = <&mx_cdev 0 0>;
				};
				modem_vdd_cdev {
					trip = <&hvx_trip>;
					cooling-device = <&modem_vdd 0 0>;
				};
				adsp_vdd_cdev {
					trip = <&hvx_trip>;
					cooling-device = <&adsp_vdd 0 0>;
				};
				slpi_vdd_cdev {
					trip = <&hvx_trip>;
					cooling-device = <&slpi_vdd 0 0>;
				};
			};
		};

		camera-lowf {
			polling-delay-passive = <0>;
			polling-delay = <0>;
			thermal-governor = "low_limits_floor";
			thermal-sensors = <&tsens1 4>;
			wake-capable-sensor;
			tracks-low;
			trips {
				camera_trip: camera-trip {
					temperature = <5000>;
					hysteresis = <5000>;
					type = "passive";
				};
			};
			cooling-maps {
				cpu0_vdd_cdev {
					trip = <&camera_trip>;
					cooling-device = <&CPU0 4 4>;
				};
				cpu4_vdd_cdev {
					trip = <&camera_trip>;
					cooling-device = <&CPU4 9 9>;
				};
				gpu_vdd_cdev {
					trip = <&camera_trip>;
					cooling-device = <&msm_gpu 1 1>;
				};
				cx_vdd_cdev {
					trip = <&camera_trip>;
					cooling-device = <&cx_cdev 0 0>;
				};
				mx_vdd_cdev {
					trip = <&camera_trip>;
					cooling-device = <&mx_cdev 0 0>;
				};
				modem_vdd_cdev {
					trip = <&camera_trip>;
					cooling-device = <&modem_vdd 0 0>;
				};
				adsp_vdd_cdev {
					trip = <&camera_trip>;
					cooling-device = <&adsp_vdd 0 0>;
				};
				slpi_vdd_cdev {
					trip = <&camera_trip>;
					cooling-device = <&slpi_vdd 0 0>;
				};
			};
		};

		mmss-lowf {
			polling-delay-passive = <0>;
			polling-delay = <0>;
			thermal-governor = "low_limits_floor";
			thermal-sensors = <&tsens1 5>;
			wake-capable-sensor;
			tracks-low;
			trips {
				mmss_trip: mmss-trip {
					temperature = <5000>;
					hysteresis = <5000>;
					type = "passive";
				};
			};
			cooling-maps {
				cpu0_vdd_cdev {
					trip = <&mmss_trip>;
					cooling-device = <&CPU0 4 4>;
				};
				cpu4_vdd_cdev {
					trip = <&mmss_trip>;
					cooling-device = <&CPU4 9 9>;
				};
				gpu_vdd_cdev {
					trip = <&mmss_trip>;
					cooling-device = <&msm_gpu 1 1>;
				};
				cx_vdd_cdev {
					trip = <&mmss_trip>;
					cooling-device = <&cx_cdev 0 0>;
				};
				mx_vdd_cdev {
					trip = <&mmss_trip>;
					cooling-device = <&mx_cdev 0 0>;
				};
				modem_vdd_cdev {
					trip = <&mmss_trip>;
					cooling-device = <&modem_vdd 0 0>;
				};
				adsp_vdd_cdev {
					trip = <&mmss_trip>;
					cooling-device = <&adsp_vdd 0 0>;
				};
				slpi_vdd_cdev {
					trip = <&mmss_trip>;
					cooling-device = <&slpi_vdd 0 0>;
				};
			};
		};

		mdm-core-lowf {
			polling-delay-passive = <0>;
			polling-delay = <0>;
			thermal-governor = "low_limits_floor";
			thermal-sensors = <&tsens1 6>;
			wake-capable-sensor;
			tracks-low;
			trips {
				mdm_trip: mdm-trip {
					temperature = <5000>;
					hysteresis = <5000>;
					type = "passive";
				};
			};
			cooling-maps {
				cpu0_vdd_cdev {
					trip = <&mdm_trip>;
					cooling-device = <&CPU0 4 4>;
				};
				cpu4_vdd_cdev {
					trip = <&mdm_trip>;
					cooling-device = <&CPU4 9 9>;
				};
				gpu_vdd_cdev {
					trip = <&mdm_trip>;
					cooling-device = <&msm_gpu 1 1>;
				};
				cx_vdd_cdev {
					trip = <&mdm_trip>;
					cooling-device = <&cx_cdev 0 0>;
				};
				mx_vdd_cdev {
					trip = <&mdm_trip>;
					cooling-device = <&mx_cdev 0 0>;
				};
				modem_vdd_cdev {
					trip = <&mdm_trip>;
					cooling-device = <&modem_vdd 0 0>;
				};
				adsp_vdd_cdev {
					trip = <&mdm_trip>;
					cooling-device = <&adsp_vdd 0 0>;
				};
				slpi_vdd_cdev {
					trip = <&mdm_trip>;
					cooling-device = <&slpi_vdd 0 0>;
				};
			};
		};
	};
};

